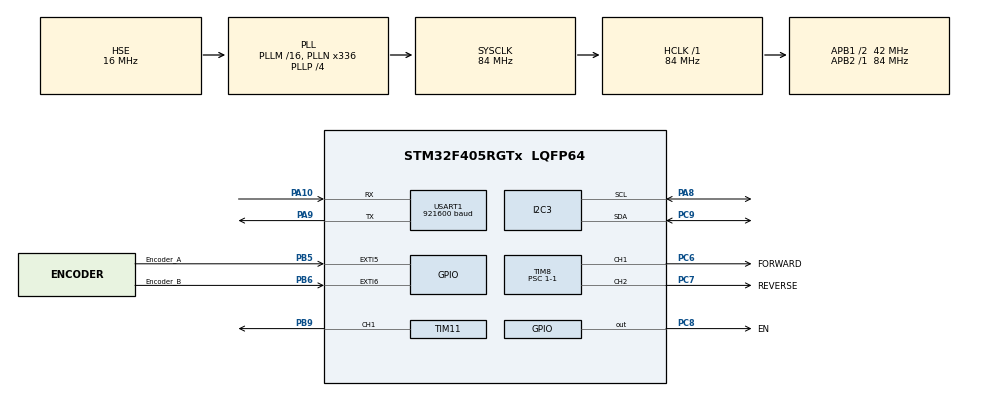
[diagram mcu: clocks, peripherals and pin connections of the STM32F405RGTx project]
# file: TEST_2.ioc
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Dma.Request0=USART1_RX
Dma.Request1=USART1_TX
Dma.USART1_RX.0.Direction=DMA_PERIPH_TO_MEMORY
Dma.USART1_RX.0.FIFOMode=DMA_FIFOMODE_DISABLE
Dma.USART1_RX.0.Instance=DMA2_Stream2
Dma.USART1_RX.0.MemDataAlignment=DMA_MDATAALIGN_BYTE
Dma.USART1_RX.0.MemInc=DMA_MINC_ENABLE
Dma.USART1_RX.0.Mode=DMA_NORMAL
Dma.USART1_RX.0.PeriphDataAlignment=DMA_PDATAALIGN_BYTE
Dma.USART1_RX.0.PeriphInc=DMA_PINC_DISABLE
Dma.USART1_RX.0.Priority=DMA_PRIORITY_LOW
Dma.USART1_TX.1.Direction=DMA_MEMORY_TO_PERIPH
Dma.USART1_TX.1.FIFOMode=DMA_FIFOMODE_DISABLE
Dma.USART1_TX.1.Instance=DMA2_Stream7
Dma.USART1_TX.1.MemDataAlignment=DMA_MDATAALIGN_BYTE
Dma.USART1_TX.1.MemInc=DMA_MINC_ENABLE
Dma.USART1_TX.1.Mode=DMA_NORMAL
Dma.USART1_TX.1.PeriphDataAlignment=DMA_PDATAALIGN_BYTE
Dma.USART1_TX.1.PeriphInc=DMA_PINC_DISABLE
Dma.USART1_TX.1.Priority=DMA_PRIORITY_LOW
Mcu.Family=STM32F4
Mcu.Name=STM32F405RGTx
Mcu.Package=LQFP64
NVIC.DMA2_Stream2_IRQn=true\:0\:0\:false\:false\:true\:false\:true\:true
NVIC.DMA2_Stream7_IRQn=true\:0\:0\:false\:false\:true\:false\:true\:true
NVIC.EXTI9_5_IRQn=true\:5\:0\:true\:false\:true\:true\:true\:true
NVIC.PriorityGroup=NVIC_PRIORITYGROUP_4
NVIC.USART1_IRQn=true\:0\:0\:false\:false\:true\:false\:true\:true
PA10.Mode=Asynchronous
PA10.Signal=USART1_RX
PA13.Mode=Serial_Wire
PA13.Signal=SYS_JTMS-SWDIO
PA14.Mode=Serial_Wire
PA14.Signal=SYS_JTCK-SWCLK
PA8.Mode=I2C
PA8.Signal=I2C3_SCL
PA9.Mode=Asynchronous
PA9.Signal=USART1_TX
PB5.GPIO_Label=Encoder_A
PB5.GPIO_ModeDefaultEXTI=GPIO_MODE_IT_RISING_FALLING
PB5.GPIO_PuPd=GPIO_NOPULL
PB5.Signal=GPXTI5
PB6.GPIO_Label=Encoder_B
PB6.GPIO_ModeDefaultEXTI=GPIO_MODE_IT_RISING_FALLING
PB6.GPIO_PuPd=GPIO_NOPULL
PB6.Signal=GPXTI6
PB9.Signal=S_TIM11_CH1
PC6.GPIO_Label=FORWARD
PC6.Signal=S_TIM8_CH1
PC7.GPIO_Label=REVERSE
PC7.Signal=S_TIM8_CH2
PC8.GPIO_Label=EN
PC8.Signal=GPIO_Output
PC9.Mode=I2C
PC9.Signal=I2C3_SDA
PH0-OSC_IN.Mode=HSE-External-Oscillator
PH0-OSC_IN.Signal=RCC_OSC_IN
PH1-OSC_OUT.Mode=HSE-External-Oscillator
PH1-OSC_OUT.Signal=RCC_OSC_OUT
ProjectManager.HeapSize=0x200
ProjectManager.StackSize=0x400
ProjectManager.TargetToolchain=STM32CubeIDE
RCC.48MHZClocksFreq_Value=84000000
RCC.AHBFreq_Value=84000000
RCC.APB1CLKDivider=RCC_HCLK_DIV2
RCC.APB1Freq_Value=42000000
RCC.APB1TimFreq_Value=84000000
RCC.APB2Freq_Value=84000000
RCC.APB2TimFreq_Value=84000000
RCC.CortexFreq_Value=84000000
RCC.HCLKFreq_Value=84000000
RCC.HSE_VALUE=16000000
RCC.HSI_VALUE=16000000
RCC.LSE_VALUE=32768
RCC.PLLN=336
RCC.PLLP=RCC_PLLP_DIV4
RCC.PLLSourceVirtual=RCC_PLLSOURCE_HSE
RCC.SYSCLKFreq_VALUE=84000000
RCC.SYSCLKSource=RCC_SYSCLKSOURCE_PLLCLK
RCC.VCOOutputFreq_Value=336000000
SH.S_TIM11_CH1.0=TIM11_CH1,PWM Generation1 CH1
SH.S_TIM8_CH1.0=TIM8_CH1,PWM Generation1 CH1
SH.S_TIM8_CH2.0=TIM8_CH2,PWM Generation2 CH2
TIM11.Channel=TIM_CHANNEL_1
TIM11.Period=20000-1
TIM11.Prescaler=84-1
TIM8.Channel-PWM\ Generation1\ CH1=TIM_CHANNEL_1
TIM8.Channel-PWM\ Generation2\ CH2=TIM_CHANNEL_2
TIM8.Period=5600-1
TIM8.Prescaler=1-1
USART1.BaudRate=921600
USART1.VirtualMode=VM_ASYNC
VP_TIM11_VS_ClockSourceINT.Mode=Enable_Timer
board=custom

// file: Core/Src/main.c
/* USER CODE BEGIN Header */
/**
  ******************************************************************************
  * @file           : main.c
  * @brief          : Main program body
  ******************************************************************************
  * @attention
  *
  * Copyright (c) 2025 STMicroelectronics.
  * All rights reserved.
  *
  * This software is licensed under terms that can be found in the LICENSE file
  * in the root directory of this software component.
  * If no LICENSE file comes with this software, it is provided AS-IS.
  *
  ******************************************************************************
  */
/* USER CODE END Header */
#include "main.h"
#include "dma.h"
#include "i2c.h"
#include "tim.h"
#include "usart.h"
#include "gpio.h"

/* USER CODE BEGIN Includes */
#include <mainpp.h>
/* USER CODE END Includes */

void SystemClock_Config(void);

int main(void)
{

  /* MCU Configuration--------------------------------------------------------*/

  /* Reset of all peripherals, Initializes the Flash interface and the Systick. */
  HAL_Init();

  /* Configure the system clock */
  SystemClock_Config();

  /* Initialize all configured peripherals */
  MX_GPIO_Init();
  MX_DMA_Init();
  MX_USART1_UART_Init();
  MX_I2C3_Init();
  MX_TIM8_Init();
  MX_TIM11_Init();
  /* USER CODE BEGIN 2 */
  setup();
  /* USER CODE END 2 */

  /* Infinite loop */
  while (1)
  {
	  loop();
  }
}

void SystemClock_Config(void)
{
  RCC_OscInitTypeDef RCC_OscInitStruct = {0};
  RCC_ClkInitTypeDef RCC_ClkInitStruct = {0};

  /** Configure the main internal regulator output voltage
  */
  __HAL_RCC_PWR_CLK_ENABLE();
  __HAL_PWR_VOLTAGESCALING_CONFIG(PWR_REGULATOR_VOLTAGE_SCALE1);

  /** Initializes the RCC Oscillators according to the specified parameters
  * in the RCC_OscInitTypeDef structure.
  */
  RCC_OscInitStruct.OscillatorType = RCC_OSCILLATORTYPE_HSE;
  RCC_OscInitStruct.HSEState = RCC_HSE_ON;
  RCC_OscInitStruct.PLL.PLLState = RCC_PLL_ON;
  RCC_OscInitStruct.PLL.PLLSource = RCC_PLLSOURCE_HSE;
  RCC_OscInitStruct.PLL.PLLM = 16;
  RCC_OscInitStruct.PLL.PLLN = 336;
  RCC_OscInitStruct.PLL.PLLP = RCC_PLLP_DIV4;
  RCC_OscInitStruct.PLL.PLLQ = 4;
  if (HAL_RCC_OscConfig(&RCC_OscInitStruct) != HAL_OK)
  {
    Error_Handler();
  }

  /** Initializes the CPU, AHB and APB buses clocks
  */
  RCC_ClkInitStruct.ClockType = RCC_CLOCKTYPE_HCLK|RCC_CLOCKTYPE_SYSCLK
                              |RCC_CLOCKTYPE_PCLK1|RCC_CLOCKTYPE_PCLK2;
  RCC_ClkInitStruct.SYSCLKSource = RCC_SYSCLKSOURCE_PLLCLK;
  RCC_ClkInitStruct.AHBCLKDivider = RCC_SYSCLK_DIV1;
  RCC_ClkInitStruct.APB1CLKDivider = RCC_HCLK_DIV2;
  RCC_ClkInitStruct.APB2CLKDivider = RCC_HCLK_DIV1;

  if (HAL_RCC_ClockConfig(&RCC_ClkInitStruct, FLASH_LATENCY_2) != HAL_OK)
  {
    Error_Handler();
  }
}

void Error_Handler(void)
{
  __disable_irq();
  while (1)
  {
  }
}
